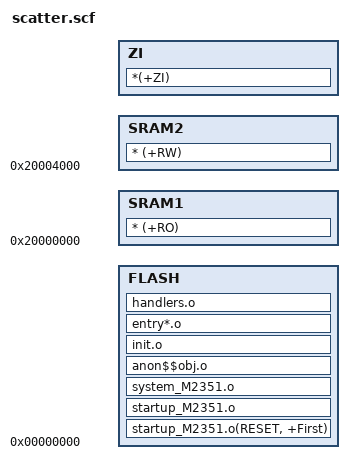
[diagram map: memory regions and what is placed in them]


FLASH 0x00000000
{
    FLASH +0
    {
         startup_M2351.o(RESET, +First)
         startup_M2351.o
         system_M2351.o
         anon$$obj.o
         init.o
         entry*.o
         handlers.o
    }

    SRAM1 0x20000000
    {  
        * (+RO)
    }

    SRAM2 0x20004000
    {
        * (+RW)
    
    }

  ZI +0
  {
    *(+ZI)
  }

}

